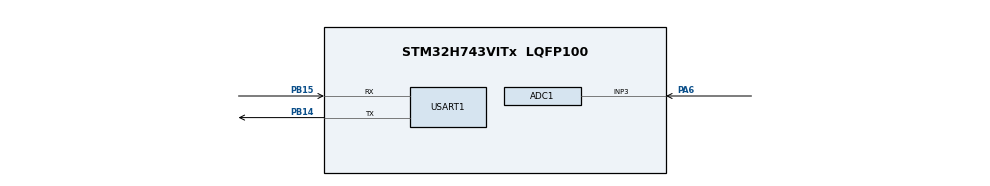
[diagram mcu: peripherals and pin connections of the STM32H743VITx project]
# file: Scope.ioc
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ADC1.Channel-0\#ChannelRegularConversion=ADC_CHANNEL_3
ADC1.ConversionDataManagement=ADC_CONVERSIONDATA_DMA_ONESHOT
ADC1.ExternalTrigConv=ADC_EXTERNALTRIG_T6_TRGO
ADC1.NbrOfConversionFlag=1
ADC1.OffsetNumber-0\#ChannelRegularConversion=ADC_OFFSET_NONE
ADC1.OffsetSignedSaturation-0\#ChannelRegularConversion=DISABLE
ADC1.Overrun=ADC_OVR_DATA_PRESERVED
ADC1.Rank-0\#ChannelRegularConversion=1
ADC1.Resolution=ADC_RESOLUTION_16B
ADC1.SamplingTime-0\#ChannelRegularConversion=ADC_SAMPLETIME_1CYCLE_5
ADC1.master=1
CORTEX_M7.CPU_ICache=Enabled
CORTEX_M7.default_mode_Activation=1
Dma.ADC1.0.Direction=DMA_PERIPH_TO_MEMORY
Dma.ADC1.0.EventEnable=DISABLE
Dma.ADC1.0.FIFOMode=DMA_FIFOMODE_DISABLE
Dma.ADC1.0.Instance=DMA1_Stream0
Dma.ADC1.0.MemDataAlignment=DMA_MDATAALIGN_HALFWORD
Dma.ADC1.0.MemInc=DMA_MINC_ENABLE
Dma.ADC1.0.Mode=DMA_NORMAL
Dma.ADC1.0.PeriphDataAlignment=DMA_PDATAALIGN_HALFWORD
Dma.ADC1.0.PeriphInc=DMA_PINC_DISABLE
Dma.ADC1.0.Polarity=HAL_DMAMUX_REQ_GEN_RISING
Dma.ADC1.0.Priority=DMA_PRIORITY_HIGH
Dma.ADC1.0.RequestNumber=1
Dma.ADC1.0.SignalID=NONE
Dma.ADC1.0.SyncEnable=DISABLE
Dma.ADC1.0.SyncPolarity=HAL_DMAMUX_SYNC_NO_EVENT
Dma.ADC1.0.SyncRequestNumber=1
Dma.ADC1.0.SyncSignalID=NONE
Dma.Request0=ADC1
Mcu.Family=STM32H7
Mcu.Name=STM32H743VITx
Mcu.Package=LQFP100
NVIC.DMA1_Stream0_IRQn=true\:0\:0\:false\:false\:true\:false\:true\:true
NVIC.PriorityGroup=NVIC_PRIORITYGROUP_4
NVIC.TIM7_IRQn=true\:15\:0\:false\:false\:true\:false\:true\:true
NVIC.TimeBase=TIM7_IRQn
NVIC.TimeBaseIP=TIM7
NVIC.USART1_IRQn=true\:0\:0\:false\:false\:true\:true\:true\:true
PA6.Signal=ADCx_INP3
PB14.GPIO_Speed=GPIO_SPEED_FREQ_VERY_HIGH
PB14.Mode=Asynchronous
PB14.Signal=USART1_TX
PB15.GPIO_Speed=GPIO_SPEED_FREQ_VERY_HIGH
PB15.Mode=Asynchronous
PB15.Signal=USART1_RX
PH0-OSC_IN\ (PH0).Mode=HSE-External-Oscillator
PH0-OSC_IN\ (PH0).Signal=RCC_OSC_IN
PH1-OSC_OUT\ (PH1).Mode=HSE-External-Oscillator
PH1-OSC_OUT\ (PH1).Signal=RCC_OSC_OUT
ProjectManager.HeapSize=0x200
ProjectManager.StackSize=0x400
ProjectManager.TargetToolchain=MDK-ARM V5.32
RCC.ADCFreq_Value=75000000
RCC.APB1Freq_Value=120000000
RCC.APB2Freq_Value=120000000
RCC.APB3Freq_Value=120000000
RCC.APB4Freq_Value=120000000
RCC.CortexFreq_Value=480000000
RCC.D1PPRE=RCC_APB3_DIV2
RCC.D2PPRE1=RCC_APB1_DIV2
RCC.D2PPRE2=RCC_APB2_DIV2
RCC.D3PPRE=RCC_APB4_DIV2
RCC.DIVM1=5
RCC.DIVM2=2
RCC.DIVN1=192
RCC.DIVN2=12
RCC.HCLKFreq_Value=240000000
RCC.HPRE=RCC_HCLK_DIV2
RCC.PLLFRACN=0
RCC.PLLSourceVirtual=RCC_PLLSOURCE_HSE
RCC.SYSCLKFreq_VALUE=480000000
RCC.SYSCLKSource=RCC_SYSCLKSOURCE_PLLCLK
RCC.USBFreq_Value=480000000
SH.ADCx_INP3.0=ADC1_INP3,IN3-Single-Ended
TIM6.AutoReloadPreload=TIM_AUTORELOAD_PRELOAD_ENABLE
TIM6.Period=79
TIM6.TIM_MasterOutputTrigger=TIM_TRGO_UPDATE
USART1.VirtualMode-Asynchronous=VM_ASYNC
VP_MEMORYMAP_VS_MEMORYMAP.Mode=CurAppReg
VP_SYS_VS_tim7.Mode=TIM7
VP_TIM6_VS_ClockSourceINT.Mode=Enable_Timer
board=custom

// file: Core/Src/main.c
/* USER CODE BEGIN Header */
/**
  ******************************************************************************
  * @file           : main.c
  * @brief          : Main program body
  ******************************************************************************
  * @attention
  *
  * Copyright (c) 2026 STMicroelectronics.
  * All rights reserved.
  *
  * This software is licensed under terms that can be found in the LICENSE file
  * in the root directory of this software component.
  * If no LICENSE file comes with this software, it is provided AS-IS.
  *
  ******************************************************************************
  */
/* USER CODE END Header */
#include "main.h"
#include "adc.h"
#include "dma.h"
#include "tim.h"
#include "usart.h"
#include "gpio.h"

/* USER CODE BEGIN Includes */
#include "mymain.h"
#include "dwin.h"
#include "fft.h"
#include "adcdac.h"
#include "fft8192.h"
/* USER CODE END Includes */

void SystemClock_Config(void);
static void MPU_Config(void);

int main(void)
{

  /* MPU Configuration--------------------------------------------------------*/
  MPU_Config();

  /* Enable the CPU Cache */

  /* Enable I-Cache---------------------------------------------------------*/
  SCB_EnableICache();

  /* MCU Configuration--------------------------------------------------------*/

  /* Reset of all peripherals, Initializes the Flash interface and the Systick. */
  HAL_Init();

  /* Configure the system clock */
  SystemClock_Config();

  /* Initialize all configured peripherals */
  MX_GPIO_Init();
  MX_DMA_Init();
  MX_ADC1_Init();
  MX_TIM6_Init();
  MX_USART1_UART_Init();
  /* USER CODE BEGIN 2 */
  ADCDAC_Init();
	FFT8192_Init();
  DWIN_Init(&huart1);
  /* USER CODE END 2 */

  /* Infinite loop */
  while (1) {

    /* USER CODE BEGIN 3 */
    //mymain_process();
		DWIN_Main();
  }
  /* USER CODE END 3 */
}

void SystemClock_Config(void)
{
  RCC_OscInitTypeDef RCC_OscInitStruct = {0};
  RCC_ClkInitTypeDef RCC_ClkInitStruct = {0};

  /** Supply configuration update enable
  */
  HAL_PWREx_ConfigSupply(PWR_LDO_SUPPLY);

  /** Configure the main internal regulator output voltage
  */
  __HAL_PWR_VOLTAGESCALING_CONFIG(PWR_REGULATOR_VOLTAGE_SCALE0);

  while(!__HAL_PWR_GET_FLAG(PWR_FLAG_VOSRDY)) {}

  /** Initializes the RCC Oscillators according to the specified parameters
  * in the RCC_OscInitTypeDef structure.
  */
  RCC_OscInitStruct.OscillatorType = RCC_OSCILLATORTYPE_HSE;
  RCC_OscInitStruct.HSEState = RCC_HSE_ON;
  RCC_OscInitStruct.PLL.PLLState = RCC_PLL_ON;
  RCC_OscInitStruct.PLL.PLLSource = RCC_PLLSOURCE_HSE;
  RCC_OscInitStruct.PLL.PLLM = 5;
  RCC_OscInitStruct.PLL.PLLN = 192;
  RCC_OscInitStruct.PLL.PLLP = 2;
  RCC_OscInitStruct.PLL.PLLQ = 2;
  RCC_OscInitStruct.PLL.PLLR = 2;
  RCC_OscInitStruct.PLL.PLLRGE = RCC_PLL1VCIRANGE_2;
  RCC_OscInitStruct.PLL.PLLVCOSEL = RCC_PLL1VCOWIDE;
  RCC_OscInitStruct.PLL.PLLFRACN = 0;
  if (HAL_RCC_OscConfig(&RCC_OscInitStruct) != HAL_OK)
  {
    Error_Handler();
  }

  /** Initializes the CPU, AHB and APB buses clocks
  */
  RCC_ClkInitStruct.ClockType = RCC_CLOCKTYPE_HCLK|RCC_CLOCKTYPE_SYSCLK
                              |RCC_CLOCKTYPE_PCLK1|RCC_CLOCKTYPE_PCLK2
                              |RCC_CLOCKTYPE_D3PCLK1|RCC_CLOCKTYPE_D1PCLK1;
  RCC_ClkInitStruct.SYSCLKSource = RCC_SYSCLKSOURCE_PLLCLK;
  RCC_ClkInitStruct.SYSCLKDivider = RCC_SYSCLK_DIV1;
  RCC_ClkInitStruct.AHBCLKDivider = RCC_HCLK_DIV2;
  RCC_ClkInitStruct.APB3CLKDivider = RCC_APB3_DIV2;
  RCC_ClkInitStruct.APB1CLKDivider = RCC_APB1_DIV2;
  RCC_ClkInitStruct.APB2CLKDivider = RCC_APB2_DIV2;
  RCC_ClkInitStruct.APB4CLKDivider = RCC_APB4_DIV2;

  if (HAL_RCC_ClockConfig(&RCC_ClkInitStruct, FLASH_LATENCY_4) != HAL_OK)
  {
    Error_Handler();
  }
}

 /* MPU Configuration */

void MPU_Config(void)
{
  MPU_Region_InitTypeDef MPU_InitStruct = {0};

  /* Disables the MPU */
  HAL_MPU_Disable();

  /** Initializes and configures the Region and the memory to be protected
  */
  MPU_InitStruct.Enable = MPU_REGION_ENABLE;
  MPU_InitStruct.Number = MPU_REGION_NUMBER0;
  MPU_InitStruct.BaseAddress = 0x0;
  MPU_InitStruct.Size = MPU_REGION_SIZE_4GB;
  MPU_InitStruct.SubRegionDisable = 0x87;
  MPU_InitStruct.TypeExtField = MPU_TEX_LEVEL0;
  MPU_InitStruct.AccessPermission = MPU_REGION_NO_ACCESS;
  MPU_InitStruct.DisableExec = MPU_INSTRUCTION_ACCESS_DISABLE;
  MPU_InitStruct.IsShareable = MPU_ACCESS_SHAREABLE;
  MPU_InitStruct.IsCacheable = MPU_ACCESS_NOT_CACHEABLE;
  MPU_InitStruct.IsBufferable = MPU_ACCESS_NOT_BUFFERABLE;

  HAL_MPU_ConfigRegion(&MPU_InitStruct);
  /* Enables the MPU */
  HAL_MPU_Enable(MPU_PRIVILEGED_DEFAULT);

}

void HAL_TIM_PeriodElapsedCallback(TIM_HandleTypeDef *htim)
{
  if (htim->Instance == TIM7)
  {
    HAL_IncTick();
  }
}

void Error_Handler(void)
{
  __disable_irq();
  while (1) {
  }
}
